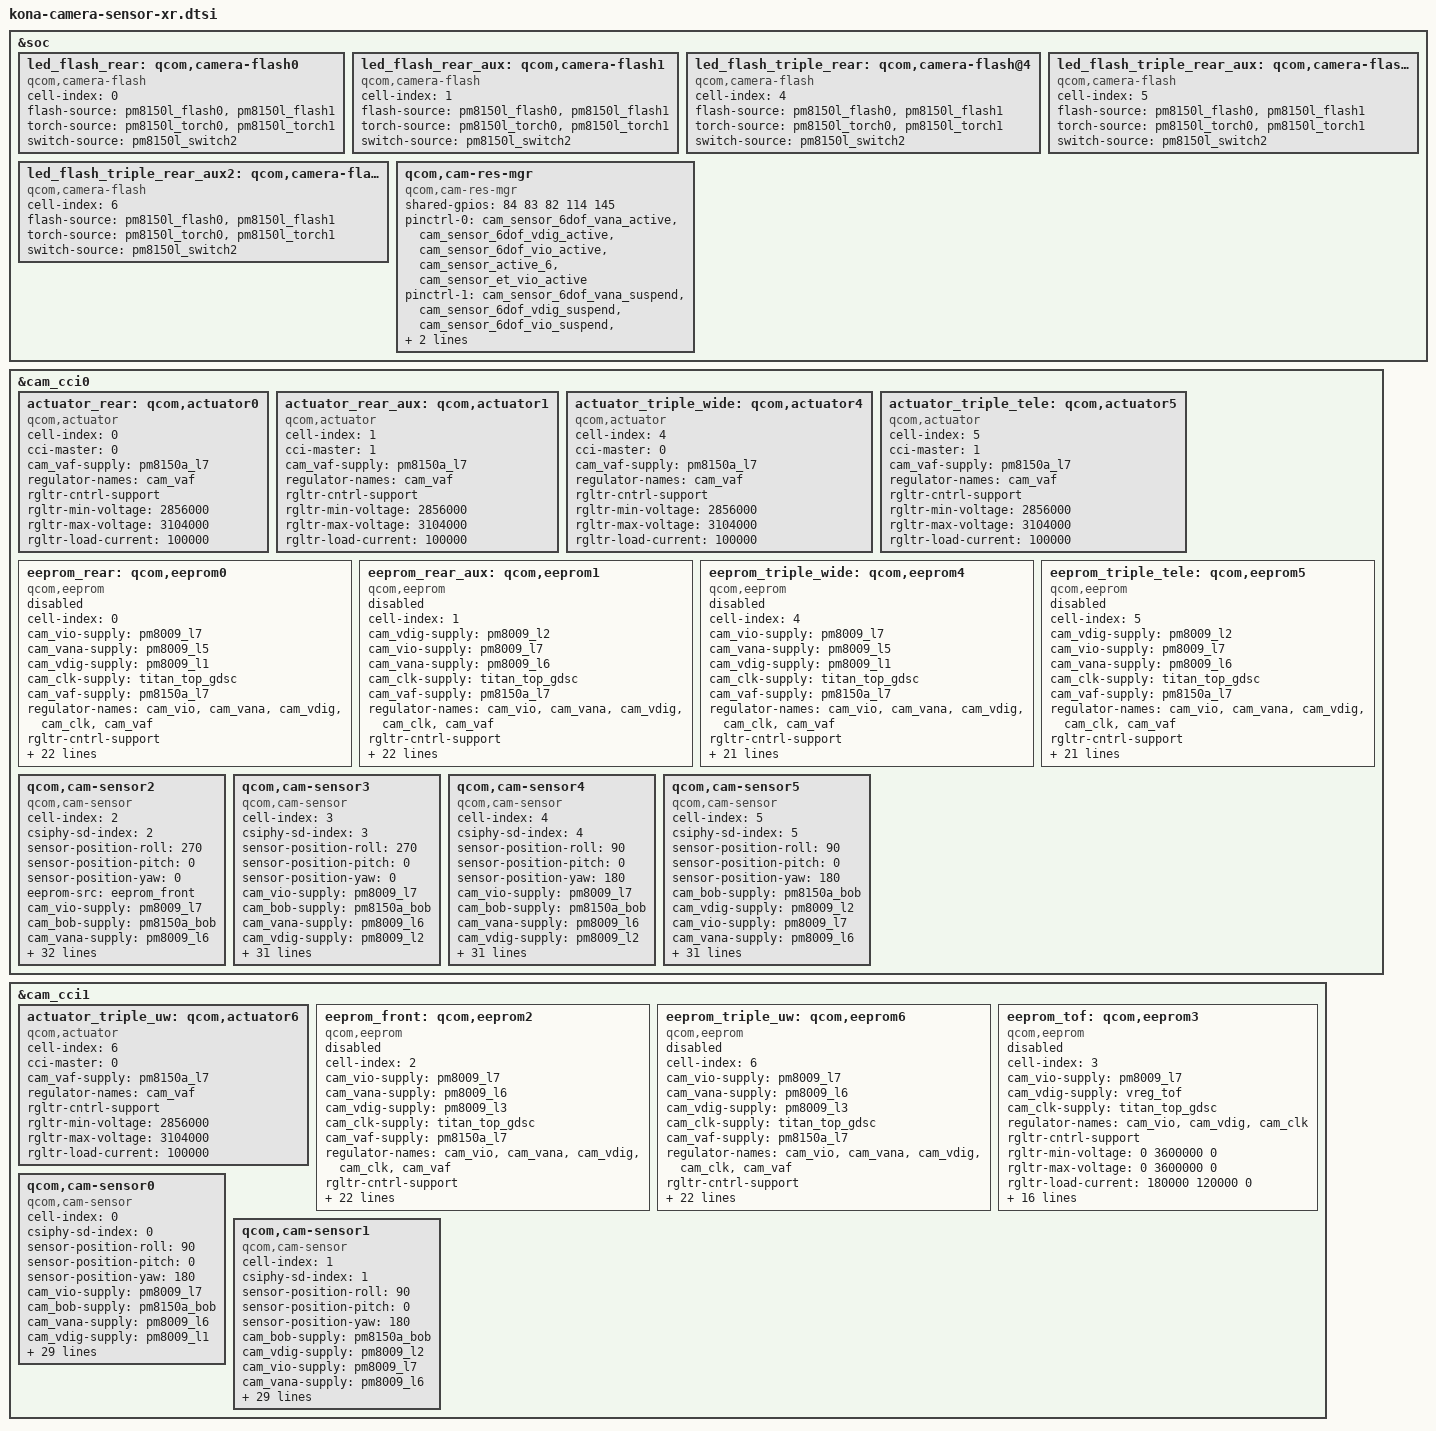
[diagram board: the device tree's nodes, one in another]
#include <dt-bindings/clock/qcom,camcc-kona.h>

&soc {
	led_flash_rear: qcom,camera-flash0 {
		cell-index = <0>;
		compatible = "qcom,camera-flash";
		flash-source = <&pm8150l_flash0 &pm8150l_flash1>;
		torch-source = <&pm8150l_torch0 &pm8150l_torch1>;
		switch-source = <&pm8150l_switch2>;
		status = "ok";
	};

	led_flash_rear_aux: qcom,camera-flash1 {
		cell-index = <1>;
		compatible = "qcom,camera-flash";
		flash-source = <&pm8150l_flash0 &pm8150l_flash1>;
		torch-source = <&pm8150l_torch0 &pm8150l_torch1>;
		switch-source = <&pm8150l_switch2>;
		status = "ok";
	};

	led_flash_triple_rear: qcom,camera-flash@4 {
		cell-index = <4>;
		compatible = "qcom,camera-flash";
		flash-source = <&pm8150l_flash0 &pm8150l_flash1>;
		torch-source = <&pm8150l_torch0 &pm8150l_torch1>;
		switch-source = <&pm8150l_switch2>;
		status = "ok";
	};

	led_flash_triple_rear_aux: qcom,camera-flash@5 {
		cell-index = <5>;
		compatible = "qcom,camera-flash";
		flash-source = <&pm8150l_flash0 &pm8150l_flash1>;
		torch-source = <&pm8150l_torch0 &pm8150l_torch1>;
		switch-source = <&pm8150l_switch2>;
		status = "ok";
	};

	led_flash_triple_rear_aux2: qcom,camera-flash@6 {
		cell-index = <6>;
		compatible = "qcom,camera-flash";
		flash-source = <&pm8150l_flash0 &pm8150l_flash1>;
		torch-source = <&pm8150l_torch0 &pm8150l_torch1>;
		switch-source = <&pm8150l_switch2>;
		status = "ok";
	};

	qcom,cam-res-mgr {
		compatible = "qcom,cam-res-mgr";
		status = "ok";
		shared-gpios = <84 83 82 114 145>;
		pinctrl-names = "cam_res_mgr_default", "cam_res_mgr_suspend";
		pinctrl-0 = <&cam_sensor_6dof_vana_active
				&cam_sensor_6dof_vdig_active
				&cam_sensor_6dof_vio_active
				&cam_sensor_active_6
				&cam_sensor_et_vio_active>;
		pinctrl-1 = <&cam_sensor_6dof_vana_suspend
				&cam_sensor_6dof_vdig_suspend
				&cam_sensor_6dof_vio_suspend
				&cam_sensor_suspend_6
				&cam_sensor_et_vio_suspend>;
	};
};

&cam_cci0 {
	actuator_rear: qcom,actuator0 {
		cell-index = <0>;
		compatible = "qcom,actuator";
		cci-master = <0>;
		cam_vaf-supply = <&pm8150a_l7>;
		regulator-names = "cam_vaf";
		rgltr-cntrl-support;
		rgltr-min-voltage = <2856000>;
		rgltr-max-voltage = <3104000>;
		rgltr-load-current = <100000>;
	};

	actuator_rear_aux: qcom,actuator1 {
		cell-index = <1>;
		compatible = "qcom,actuator";
		cci-master = <1>;
		cam_vaf-supply = <&pm8150a_l7>;
		regulator-names = "cam_vaf";
		rgltr-cntrl-support;
		rgltr-min-voltage = <2856000>;
		rgltr-max-voltage = <3104000>;
		rgltr-load-current = <100000>;
	};

	actuator_triple_wide: qcom,actuator4 {
		cell-index = <4>;
		compatible = "qcom,actuator";
		cci-master = <0>;
		cam_vaf-supply = <&pm8150a_l7>;
		regulator-names = "cam_vaf";
		rgltr-cntrl-support;
		rgltr-min-voltage = <2856000>;
		rgltr-max-voltage = <3104000>;
		rgltr-load-current = <100000>;
	};

	actuator_triple_tele: qcom,actuator5 {
		cell-index = <5>;
		compatible = "qcom,actuator";
		cci-master = <1>;
		cam_vaf-supply = <&pm8150a_l7>;
		regulator-names = "cam_vaf";
		rgltr-cntrl-support;
		rgltr-min-voltage = <2856000>;
		rgltr-max-voltage = <3104000>;
		rgltr-load-current = <100000>;
	};

	eeprom_rear: qcom,eeprom0 {
		cell-index = <0>;
		compatible = "qcom,eeprom";
		cam_vio-supply = <&pm8009_l7>;
		cam_vana-supply = <&pm8009_l5>;
		cam_vdig-supply = <&pm8009_l1>;
		cam_clk-supply = <&titan_top_gdsc>;
		cam_vaf-supply = <&pm8150a_l7>;
		regulator-names = "cam_vio", "cam_vana", "cam_vdig",
			"cam_clk", "cam_vaf";
		rgltr-cntrl-support;
		rgltr-min-voltage = <1800000 2800000 1104000 0 2856000>;
		rgltr-max-voltage = <1800000 3000000 1104000 0 3104000>;
		rgltr-load-current = <120000 80000 1200000 0 100000>;
		gpio-no-mux = <0>;
		pinctrl-names = "cam_default", "cam_suspend";
		pinctrl-0 = <&cam_sensor_mclk0_active
				&cam_sensor_active_rear>;
		pinctrl-1 = <&cam_sensor_mclk0_suspend
				&cam_sensor_suspend_rear>;
		gpios = <&tlmm 94 0>,
			<&tlmm 93 0>;
		gpio-reset = <1>;
		gpio-req-tbl-num = <0 1>;
		gpio-req-tbl-flags = <1 0>;
		gpio-req-tbl-label = "CAMIF_MCLK0",
					"CAM_RESET0";
		sensor-position = <0>;
		sensor-mode = <0>;
		cci-master = <0>;
		status = "disabled";
		clocks = <&clock_camcc CAM_CC_MCLK0_CLK>;
		clock-names = "cam_clk";
		clock-cntl-level = "turbo";
		clock-rates = <24000000>;
	};

	eeprom_rear_aux: qcom,eeprom1 {
		cell-index = <1>;
		compatible = "qcom,eeprom";
		cam_vdig-supply = <&pm8009_l2>;
		cam_vio-supply = <&pm8009_l7>;
		cam_vana-supply = <&pm8009_l6>;
		cam_clk-supply = <&titan_top_gdsc>;
		cam_vaf-supply = <&pm8150a_l7>;
		regulator-names = "cam_vio", "cam_vana", "cam_vdig",
			"cam_clk", "cam_vaf";
		rgltr-cntrl-support;
		rgltr-min-voltage = <1800000 2800000 1200000 0 2856000>;
		rgltr-max-voltage = <1800000 3000000 1200000 0 3104000>;
		rgltr-load-current = <120000 80000 1200000 0 100000>;
		gpio-no-mux = <0>;
		pinctrl-names = "cam_default", "cam_suspend";
		pinctrl-0 = <&cam_sensor_mclk1_active
				 &cam_sensor_active_rear_aux>;
		pinctrl-1 = <&cam_sensor_mclk1_suspend
				 &cam_sensor_suspend_rear_aux>;
		gpios = <&tlmm 95 0>,
			<&tlmm 92 0>;
		gpio-reset = <1>;
		gpio-req-tbl-num = <0 1>;
		gpio-req-tbl-flags = <1 0>;
		gpio-req-tbl-label = "CAMIF_MCLK1",
					"CAM_RESET1";
		sensor-position = <0>;
		sensor-mode = <0>;
		cci-master = <1>;
		status = "disabled";
		clocks = <&clock_camcc CAM_CC_MCLK2_CLK>;
		clock-names = "cam_clk";
		clock-cntl-level = "turbo";
		clock-rates = <24000000>;
	};

	eeprom_triple_wide: qcom,eeprom4 {
		cell-index = <4>;
		compatible = "qcom,eeprom";
		cam_vio-supply = <&pm8009_l7>;
		cam_vana-supply = <&pm8009_l5>;
		cam_vdig-supply = <&pm8009_l1>;
		cam_clk-supply = <&titan_top_gdsc>;
		cam_vaf-supply = <&pm8150a_l7>;
		regulator-names = "cam_vio", "cam_vana", "cam_vdig",
			"cam_clk", "cam_vaf";
		rgltr-cntrl-support;
		rgltr-min-voltage = <1800000 2800000 1104000 0 2856000>;
		rgltr-max-voltage = <1800000 3000000 1104000 0 3104000>;
		rgltr-load-current = <120000 80000 1200000 0 0>;
		gpio-no-mux = <0>;
		pinctrl-names = "cam_default", "cam_suspend";
		pinctrl-0 = <&cam_sensor_mclk0_active
				&cam_sensor_active_rear>;
		pinctrl-1 = <&cam_sensor_mclk0_suspend
				&cam_sensor_suspend_rear>;
		gpios = <&tlmm 94 0>,
			<&tlmm 93 0>;
		gpio-reset = <1>;
		gpio-req-tbl-num = <0 1>;
		gpio-req-tbl-flags = <1 0>;
		gpio-req-tbl-label = "CAMIF_MCLK0",
					"CAM_RESET0";
		sensor-position = <0>;
		sensor-mode = <0>;
		cci-master = <0>;
		status = "disabled";
		clocks = <&clock_camcc CAM_CC_MCLK0_CLK>;
		clock-names = "cam_clk";
		clock-cntl-level = "turbo";
		clock-rates = <24000000>;
	};

	eeprom_triple_tele: qcom,eeprom5 {
		cell-index = <5>;
		compatible = "qcom,eeprom";
		cam_vdig-supply = <&pm8009_l2>;
		cam_vio-supply = <&pm8009_l7>;
		cam_vana-supply = <&pm8009_l6>;
		cam_clk-supply = <&titan_top_gdsc>;
		cam_vaf-supply = <&pm8150a_l7>;
		regulator-names = "cam_vio", "cam_vana", "cam_vdig",
			"cam_clk", "cam_vaf";
		rgltr-cntrl-support;
		rgltr-min-voltage = <1800000 2800000 1200000 0 2856000>;
		rgltr-max-voltage = <1800000 3000000 1200000 0 3104000>;
		rgltr-load-current = <120000 80000 1200000 0 0>;
		gpio-no-mux = <0>;
		pinctrl-names = "cam_default", "cam_suspend";
		pinctrl-0 = <&cam_sensor_mclk1_active
				 &cam_sensor_active_rear_aux>;
		pinctrl-1 = <&cam_sensor_mclk1_suspend
				 &cam_sensor_suspend_rear_aux>;
		gpios = <&tlmm 95 0>,
			<&tlmm 92 0>;
		gpio-reset = <1>;
		gpio-req-tbl-num = <0 1>;
		gpio-req-tbl-flags = <1 0>;
		gpio-req-tbl-label = "CAMIF_MCLK1",
					"CAM_RESET1";
		sensor-position = <0>;
		sensor-mode = <0>;
		cci-master = <0>;
		status = "disabled";
		clocks = <&clock_camcc CAM_CC_MCLK2_CLK>;
		clock-names = "cam_clk";
		clock-cntl-level = "turbo";
		clock-rates = <24000000>;
	};
	/* RGB Left (Master) */
	qcom,cam-sensor2 {
		cell-index = <2>;
		compatible = "qcom,cam-sensor";
		csiphy-sd-index = <2>;
		sensor-position-roll = <270>;
		sensor-position-pitch = <0>;
		sensor-position-yaw = <0>;
		eeprom-src = <&eeprom_front>;
		cam_vio-supply = <&pm8009_l7>;
		cam_bob-supply = <&pm8150a_bob>;
		cam_vana-supply = <&pm8009_l6>;
		cam_vdig-supply = <&pm8009_l2>;
		cam_clk-supply = <&titan_top_gdsc>;
		regulator-names = "cam_vio", "cam_vana", "cam_vdig",
			"cam_clk", "cam_bob";
		rgltr-cntrl-support;
		pwm-switch;
		rgltr-min-voltage = <1800000 2800000 1200000 0 3008000>;
		rgltr-max-voltage = <1800000 3000000 1200000 0 3960000>;
		rgltr-load-current = <600000 80000 1200000 0 2000000>;
		gpio-no-mux = <0>;
		pinctrl-names = "cam_default", "cam_suspend";
		pinctrl-0 = <&cam_sensor_mclk2_active
				 &cam_sensor_active_rgbleft>;
		pinctrl-1 = <&cam_sensor_mclk2_suspend
				 &cam_sensor_suspend_rgbleft>;
		gpios = <&tlmm 96 0>,
			<&tlmm 78 0>,
			<&tlmm 117 0>,
			<&tlmm 116 0>,
			<&tlmm 115 0>;
		gpio-reset = <1>;
		gpio-vana = <2>;
		gpio-vio = <3>;
		gpio-vdig = <4>;
		gpio-req-tbl-num = <0 1 2 3 4>;
		gpio-req-tbl-flags = <1 0 0 0 0>;
		gpio-req-tbl-label = "CAMIF_MCLK2",
					"CAM_RESET2",
					"CAM_VANA2",
					"CAM_VIO2",
					"CAM_VDIG2";
		sensor-mode = <0>;
		cci-master = <0>;
		status = "ok";
		clocks = <&clock_camcc CAM_CC_MCLK2_CLK>;
		clock-names = "cam_clk";
		clock-cntl-level = "turbo";
		clock-rates = <24000000>;
	};
	/* RGB Right(Slave) */
	qcom,cam-sensor3 {
		cell-index = <3>;
		compatible = "qcom,cam-sensor";
		csiphy-sd-index = <3>;
		sensor-position-roll = <270>;
		sensor-position-pitch = <0>;
		sensor-position-yaw = <0>;
		cam_vio-supply = <&pm8009_l7>;
		cam_bob-supply = <&pm8150a_bob>;
		cam_vana-supply = <&pm8009_l6>;
		cam_vdig-supply = <&pm8009_l2>;
		cam_clk-supply = <&titan_top_gdsc>;
		regulator-names = "cam_vio", "cam_vana", "cam_vdig",
			"cam_clk", "cam_bob";
		rgltr-cntrl-support;
		pwm-switch;
		rgltr-min-voltage = <1800000 2800000 1200000 0 3008000>;
		rgltr-max-voltage = <1800000 3000000 1200000 0 3960000>;
		rgltr-load-current = <600000 80000 1200000 0 2000000>;
		gpio-no-mux = <0>;
		pinctrl-names = "cam_default", "cam_suspend";
		pinctrl-0 = <&cam_sensor_mclk3_active
				 &cam_sensor_active_rgbright>;
		pinctrl-1 = <&cam_sensor_mclk3_suspend
				 &cam_sensor_suspend_rgbright>;
		gpios = <&tlmm 97 0>,
			<&tlmm 109 0>,
			<&tlmm 117 0>,
			<&tlmm 116 0>,
			<&tlmm 115 0>;
		gpio-reset = <1>;
		gpio-vana = <2>;
		gpio-vio = <3>;
		gpio-vdig = <4>;
		gpio-req-tbl-num = <0 1 2 3 4>;
		gpio-req-tbl-flags = <1 0 0 0 0>;
		gpio-req-tbl-label = "CAMIF_MCLK3",
					"CAM_RESET3",
					"CAM_VANA3",
					"CAM_VIO3",
					"CAM_VDIG3";
		sensor-mode = <0>;
		cci-master = <1>;
		status = "ok";
		clocks = <&clock_camcc CAM_CC_MCLK3_CLK>;
		clock-names = "cam_clk";
		clock-cntl-level = "turbo";
		clock-rates = <24000000>;
	};
	/* 6DOF Left (Slave) */
	qcom,cam-sensor4 {
		cell-index = <4>;
		compatible = "qcom,cam-sensor";
		csiphy-sd-index = <4>;
		sensor-position-roll = <90>;
		sensor-position-pitch = <0>;
		sensor-position-yaw = <180>;
		cam_vio-supply = <&pm8009_l7>;
		cam_bob-supply = <&pm8150a_bob>;
		cam_vana-supply = <&pm8009_l6>;
		cam_vdig-supply = <&pm8009_l2>;
		cam_clk-supply = <&titan_top_gdsc>;
		regulator-names = "cam_vio", "cam_vana", "cam_vdig",
			"cam_clk", "cam_bob";
		rgltr-cntrl-support;
		pwm-switch;
		rgltr-min-voltage = <1800000 2800000 1200000 0 3008000>;
		rgltr-max-voltage = <1800000 3000000 1200000 0 3960000>;
		rgltr-load-current = <6000000 80000 1200000 0 2000000>;
		gpio-no-mux = <0>;
		pinctrl-names = "cam_default", "cam_suspend";
		pinctrl-0 = <&cam_sensor_mclk4_active
				&cam_sensor_active_6dofright>;
		pinctrl-1 = <&cam_sensor_mclk4_suspend
				&cam_sensor_suspend_6dofright>;
		gpios = <&tlmm 98 0>,
			<&tlmm 131 0>,
			<&tlmm 84 0>,
			<&tlmm 83 0>,
			<&tlmm 82 0>;
		gpio-reset = <1>;
		gpio-vana = <2>;
		gpio-vio = <3>;
		gpio-vdig = <4>;
		gpio-req-tbl-num = <0 1 2 3 4>;
		gpio-req-tbl-flags = <1 0 0 0 0>;
		gpio-req-tbl-label = "CAMIF_MCLK4",
					"CAM_RESET4",
					"CAM_VANA4",
					"CAM_VIO4",
					"CAM_VDIG4";
		sensor-mode = <0>;
		cci-master = <1>;
		status = "ok";
		clocks = <&clock_camcc CAM_CC_MCLK4_CLK>;
		clock-names = "cam_clk";
		clock-cntl-level = "turbo";
		clock-rates = <24000000>;
	};
      /* 6DOF Right (Master) */
	qcom,cam-sensor5 {
		cell-index = <5>;
		compatible = "qcom,cam-sensor";
		csiphy-sd-index = <5>;
		sensor-position-roll = <90>;
		sensor-position-pitch = <0>;
		sensor-position-yaw = <180>;
		cam_bob-supply = <&pm8150a_bob>;
		cam_vdig-supply = <&pm8009_l2>;
		cam_vio-supply = <&pm8009_l7>;
		cam_vana-supply = <&pm8009_l6>;
		cam_clk-supply = <&titan_top_gdsc>;
		regulator-names = "cam_vio", "cam_vana", "cam_vdig",
			"cam_clk", "cam_bob";
		rgltr-cntrl-support;
		pwm-switch;
		rgltr-min-voltage = <1800000 2800000 1200000 0 3008000>;
		rgltr-max-voltage = <1800000 3000000 1200000 0 3960000>;
		rgltr-load-current = <6000000 80000 1200000 0 2000000>;
		gpio-no-mux = <0>;
		pinctrl-names = "cam_default", "cam_suspend";
		pinctrl-0 = <&cam_sensor_mclk5_active
				&cam_sensor_active_6dofleft>;
		pinctrl-1 = <&cam_sensor_mclk5_suspend
				&cam_sensor_suspend_6dofleft>;
		gpios = <&tlmm 99 0>,
			<&tlmm 130 0>,
			<&tlmm 84 0>,
			<&tlmm 83 0>,
			<&tlmm 82 0>;
		gpio-reset = <1>;
		gpio-vana = <2>;
		gpio-vio = <3>;
		gpio-vdig = <4>;
		gpio-req-tbl-num = <0 1 2 3 4>;
		gpio-req-tbl-flags = <1 0 0 0 0>;
		gpio-req-tbl-label = "CAMIF_MCLK5",
					"CAM_RESET5",
					"CAM_VANA5",
					"CAM_VIO5",
					"CAM_VDIG5";
		sensor-mode = <0>;
		cci-master = <0>;
		status = "ok";
		clocks = <&clock_camcc CAM_CC_MCLK5_CLK>;
		clock-names = "cam_clk";
		clock-cntl-level = "turbo";
		clock-rates = <24000000>;
	};


};

&cam_cci1 {
	actuator_triple_uw: qcom,actuator6 {
		cell-index = <6>;
		compatible = "qcom,actuator";
		cci-master = <0>;
		cam_vaf-supply = <&pm8150a_l7>;
		regulator-names = "cam_vaf";
		rgltr-cntrl-support;
		rgltr-min-voltage = <2856000>;
		rgltr-max-voltage = <3104000>;
		rgltr-load-current = <100000>;
	};

	eeprom_front: qcom,eeprom2 {
		cell-index = <2>;
		compatible = "qcom,eeprom";
		cam_vio-supply = <&pm8009_l7>;
		cam_vana-supply = <&pm8009_l6>;
		cam_vdig-supply = <&pm8009_l3>;
		cam_clk-supply = <&titan_top_gdsc>;
		cam_vaf-supply = <&pm8150a_l7>;
		regulator-names = "cam_vio", "cam_vana", "cam_vdig",
			"cam_clk", "cam_vaf";
		rgltr-cntrl-support;
		rgltr-min-voltage = <1800000 2800000 1056000 0 2856000>;
		rgltr-max-voltage = <1800000 3000000 1056000 0 3104000>;
		rgltr-load-current = <120000 80000 1200000 0 100000>;
		gpio-no-mux = <0>;
		pinctrl-names = "cam_default", "cam_suspend";
		pinctrl-0 = <&cam_sensor_mclk2_active
				 &cam_sensor_active_rst2>;
		pinctrl-1 = <&cam_sensor_mclk2_suspend
				 &cam_sensor_suspend_rst2>;
		gpios = <&tlmm 96 0>,
			<&tlmm 78 0>;
		gpio-reset = <1>;
		gpio-req-tbl-num = <0 1>;
		gpio-req-tbl-flags = <1 0>;
		gpio-req-tbl-label = "CAMIF_MCLK2",
					"CAM_RESET2";
		sensor-position = <1>;
		sensor-mode = <0>;
		cci-master = <0>;
		status = "disabled";
		clocks = <&clock_camcc CAM_CC_MCLK2_CLK>;
		clock-names = "cam_clk";
		clock-cntl-level = "turbo";
		clock-rates = <24000000>;
	};

	eeprom_triple_uw: qcom,eeprom6 {
		cell-index = <6>;
		compatible = "qcom,eeprom";
		cam_vio-supply = <&pm8009_l7>;
		cam_vana-supply = <&pm8009_l6>;
		cam_vdig-supply = <&pm8009_l3>;
		cam_clk-supply = <&titan_top_gdsc>;
		cam_vaf-supply = <&pm8150a_l7>;
		regulator-names = "cam_vio", "cam_vana", "cam_vdig",
			"cam_clk", "cam_vaf";
		rgltr-cntrl-support;
		rgltr-min-voltage = <1800000 2800000 1056000 0 2856000>;
		rgltr-max-voltage = <1800000 3000000 1056000 0 3104000>;
		rgltr-load-current = <120000 80000 1200000 0 100000>;
		gpio-no-mux = <0>;
		pinctrl-names = "cam_default", "cam_suspend";
		pinctrl-0 = <&cam_sensor_mclk2_active
				 &cam_sensor_active_rst2>;
		pinctrl-1 = <&cam_sensor_mclk2_suspend
				 &cam_sensor_suspend_rst2>;
		gpios = <&tlmm 96 0>,
			<&tlmm 78 0>;
		gpio-reset = <1>;
		gpio-req-tbl-num = <0 1>;
		gpio-req-tbl-flags = <1 0>;
		gpio-req-tbl-label = "CAMIF_MCLK2",
					"CAM_RESET2";
		sensor-position = <1>;
		sensor-mode = <0>;
		cci-master = <0>;
		status = "disabled";
		clocks = <&clock_camcc CAM_CC_MCLK2_CLK>;
		clock-names = "cam_clk";
		clock-cntl-level = "turbo";
		clock-rates = <24000000>;
	};

	eeprom_tof: qcom,eeprom3 {
		cell-index = <3>;
		compatible = "qcom,eeprom";
		cam_vio-supply = <&pm8009_l7>;
		cam_vdig-supply = <&vreg_tof>;
		cam_clk-supply = <&titan_top_gdsc>;
		regulator-names = "cam_vio", "cam_vdig",
			"cam_clk";
		rgltr-cntrl-support;
		rgltr-min-voltage = <0 3600000 0>;
		rgltr-max-voltage = <0 3600000 0>;
		rgltr-load-current = <180000 120000 0>;
		gpio-no-mux = <0>;
		pinctrl-names = "cam_default", "cam_suspend";
		pinctrl-0 = <&cam_sensor_mclk3_active
			&cam_sensor_active_3>;
		pinctrl-1 = <&cam_sensor_mclk3_suspend
			&cam_sensor_suspend_3>;
		gpios = <&tlmm 97 0>,
			<&tlmm 109 0>;
		gpio-reset = <1>;
		gpio-req-tbl-num = <0 1>;
		gpio-req-tbl-flags = <1 0>;
		gpio-req-tbl-label = "CAMIF_MCLK3",
			"CAM_RESET3";
		sensor-position = <1>;
		sensor-mode = <0>;
		cci-master = <1>;
		status = "disabled";
		clocks = <&clock_camcc CAM_CC_MCLK3_CLK>;
		clock-names = "cam_clk";
		clock-cntl-level = "turbo";
		clock-rates = <24000000>;
	};

	/* ET LEFT (Master) */
	qcom,cam-sensor0 {
		cell-index = <0>;
		compatible = "qcom,cam-sensor";
		csiphy-sd-index = <0>;
		sensor-position-roll = <90>;
		sensor-position-pitch = <0>;
		sensor-position-yaw = <180>;
		cam_vio-supply = <&pm8009_l7>;
		cam_bob-supply = <&pm8150a_bob>;
		cam_vana-supply = <&pm8009_l6>;
		cam_vdig-supply = <&pm8009_l1>;
		cam_clk-supply = <&titan_top_gdsc>;
		regulator-names = "cam_vio", "cam_vana", "cam_vdig",
			"cam_clk", "cam_bob";
		rgltr-cntrl-support;
		pwm-switch;
		rgltr-min-voltage = <1800000 2800000 1104000 0 3008000>;
		rgltr-max-voltage = <1800000 3000000 1104000 0 3960000>;
		rgltr-load-current = <600000 80000 1200000 0 2000000>;
		gpio-no-mux = <0>;
		pinctrl-names = "cam_default", "cam_suspend";
		pinctrl-0 = <&cam_sensor_mclk0_active
				&cam_sensor_active_etleft>;
		pinctrl-1 = <&cam_sensor_mclk0_suspend
				&cam_sensor_suspend_etleft>;
		gpios = <&tlmm 94 0>,
			<&tlmm 93 0>,
			<&tlmm 114 0>,
			<&tlmm 145 0>;
		gpio-reset = <1>;
		gpio-vana = <2>;
		gpio-vio = <3>;
		gpio-req-tbl-num = <0 1 2 3>;
		gpio-req-tbl-flags = <1 0 0 0>;
		gpio-req-tbl-label = "CAMIF_MCLK0",
					"CAM_RESET0",
					"CAM_VANA0",
					"CAM_VIO0";
		sensor-mode = <0>;
		cci-master = <0>;
		status = "ok";
		clocks = <&clock_camcc CAM_CC_MCLK0_CLK>;
		clock-names = "cam_clk";
		clock-cntl-level = "turbo";
		clock-rates = <24000000>;
	};

	/* ET RIGHT (Left) */
	qcom,cam-sensor1 {
		cell-index = <1>;
		compatible = "qcom,cam-sensor";
		csiphy-sd-index = <1>;
		sensor-position-roll = <90>;
		sensor-position-pitch = <0>;
		sensor-position-yaw = <180>;
		cam_bob-supply = <&pm8150a_bob>;
		cam_vdig-supply = <&pm8009_l2>;
		cam_vio-supply = <&pm8009_l7>;
		cam_vana-supply = <&pm8009_l6>;
		cam_clk-supply = <&titan_top_gdsc>;
		regulator-names = "cam_vio", "cam_vana", "cam_vdig",
			"cam_clk", "cam_bob";
		rgltr-cntrl-support;
		pwm-switch;
		rgltr-min-voltage = <1800000 2800000 1200000 0 3008000>;
		rgltr-max-voltage = <1800000 3000000 1200000 0 3960000>;
		rgltr-load-current = <600000 80000 1200000 0 2000000>;
		gpio-no-mux = <0>;
		pinctrl-names = "cam_default", "cam_suspend";
		pinctrl-0 = <&cam_sensor_mclk1_active
				&cam_sensor_active_etright>;
		pinctrl-1 = <&cam_sensor_mclk1_suspend
				&cam_sensor_suspend_etright>;
		gpios = <&tlmm 95 0>,
			<&tlmm 92 0>,
			<&tlmm 114 0>,
			<&tlmm 145 0>;
		gpio-reset = <1>;
		gpio-vana = <2>;
		gpio-vio = <3>;
		gpio-req-tbl-num = <0 1 2 3>;
		gpio-req-tbl-flags = <1 0 0 0>;
		gpio-req-tbl-label = "CAMIF_MCLK1",
					"CAM_RESET1",
					"CAM_VANA1",
					"CAM_VIO1";
		sensor-mode = <0>;
		cci-master = <1>;
		status = "ok";
		clocks = <&clock_camcc CAM_CC_MCLK1_CLK>;
		clock-names = "cam_clk";
		clock-cntl-level = "turbo";
		clock-rates = <24000000>;
	};

};

